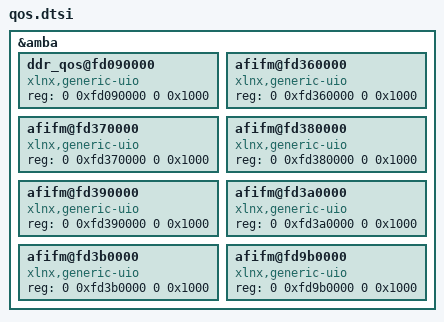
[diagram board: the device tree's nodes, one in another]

&amba {

    ddr_qos@fd090000 {
        compatible = "xlnx,generic-uio";
        reg = <0 0xfd090000 0 0x1000>;
    };

    afifm@fd360000 {
        compatible = "xlnx,generic-uio";
        reg = <0 0xfd360000 0 0x1000>;
    };

    afifm@fd370000 {
        compatible = "xlnx,generic-uio";
        reg = <0 0xfd370000 0 0x1000>;
    };

    afifm@fd380000 {
        compatible = "xlnx,generic-uio";
        reg = <0 0xfd380000 0 0x1000>;
    };

    afifm@fd390000 {
        compatible = "xlnx,generic-uio";
        reg = <0 0xfd390000 0 0x1000>;
    };

    afifm@fd3a0000 {
        compatible = "xlnx,generic-uio";
        reg = <0 0xfd3a0000 0 0x1000>;
    };

    afifm@fd3b0000 {
        compatible = "xlnx,generic-uio";
        reg = <0 0xfd3b0000 0 0x1000>;
    };

    afifm@fd9b0000 {
        compatible = "xlnx,generic-uio";
        reg = <0 0xfd9b0000 0 0x1000>;
    };
};
